# MKE15Z7 register map
Vendor: Freescale Semiconductor, Inc.; Series: Kinetis_E; File version: 1.6
CPU: CM0PLUS r0p0, little endian, no MPU, no FPU, VTOR, 2 interrupt priority bits
Registers are 32-bit, read-write, reset 0x0 unless marked. A register's access mark holds for its fields unless they carry their own. Offsets are from the block's base; [hi:lo] are bit positions; {n}, {i} and the like mark numbered series.

## SIM — System Integration Module
Base 0x40048000; register names take the prefix SIM_
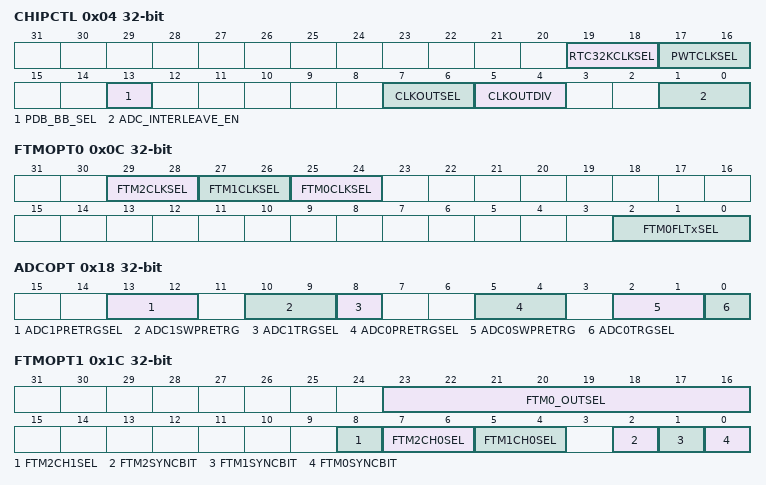
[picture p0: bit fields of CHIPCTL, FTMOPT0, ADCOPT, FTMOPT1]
0x04 CHIPCTL — Chip Control register
  [19:18] RTC32KCLKSEL — RTC 32K clock input select
    0=OSC32 clock output; 1=RTC_CLKIN
  [17:16] PWTCLKSEL — PWT clock source select
    0=PWT alternative clock is from the TCLK0 pin; 1=PWT alternative clock is from the TCLK1 pin; 2=PWT alternative clock is from the TCLK2 pin
  [13] PDB_BB_SEL — PDB back-to-back select
    0=PDB0 channel 0 back-to-back operation with ADC0 COCO[1:0] and PDB0 channel 1 back-to-back operation with ADC1 COCO[1:0]; 1=PDB0 Channel 0 back-to-back operation with COCO[0] of ADC0 and COCO[1] of ADC1 ; PDB0 Channel 1 back-to-back operation with COCO[0] of ADC1 and COCO[1] of ADC0
  [7:6] CLKOUTSEL — CLKOUT Select
    0=Reseved; 1=SCGCLKOUT(SIRC/FIRC/SOSC/LPFLL), see SCG_CLKOUTCNFG register; 2=RTC oscillator (OSC32) clock (32 kHz); 3=LPO clock (128 kHz)
  [5:4] CLKOUTDIV — CLKOUT divider ratio
    0=Divided by 1; 1=Divided by 2; 2=Divided by 4; 3=Divided by 8
  [1:0] ADC_INTERLEAVE_EN — ADC interleave channel enable
    0=No interleave channel
0x0C FTMOPT0 — FTM Option Register 0
  [29:28] FTM2CLKSEL — FTM2 External Clock Pin Select
    0=FTM2 external clock driven by TCLK0 pin; 1=FTM2 external clock driven by TCLK1 pin; 2=FTM2 external clock driven by TCLK2 pin; 3=No clock input
  [27:26] FTM1CLKSEL — FTM1 External Clock Pin Select
    0=FTM1 external clock driven by TCLK0 pin; 1=FTM1 external clock driven by TCLK1 pin; 2=FTM1 external clock driven by TCLK2 pin; 3=No clock input
  [25:24] FTM0CLKSEL — FTM0 External Clock Pin Select
    0=FTM0 external clock driven by TCLK0 pin; 1=FTM0 external clock driven by TCLK1 pin; 2=FTM0 external clock driven by TCLK2 pin; 3=No clock input
  [2:0] FTM0FLTxSEL — FTM0 Fault x Select
0x18 ADCOPT — ADC Options Register
  [13:12] ADC1PRETRGSEL — ADC1 pre-trigger source select
    0=PDB output; 1=TRGMUX output; 2=ADC1 software pre-trigger
  [10:9] ADC1SWPRETRG — ADC1 software pre-trigger sources
    {v}=software pre-trigger {v} (v=0..3)
  [8] ADC1TRGSEL — ADC1 trigger source select
    0=PDB output; 1=TRGMUX output
  [5:4] ADC0PRETRGSEL — ADC0 pre-trigger source select
    0=PDB output; 1=TRGMUX output; 2=ADC0 software pre-trigger
  [2:1] ADC0SWPRETRG — ADC0 software pre-trigger sources
    {v}=software pre-trigger {v} (v=0..3)
  [0] ADC0TRGSEL — ADC0 trigger source select
    0=PDB output; 1=TRGMUX output
0x1C FTMOPT1 — FTM Option Register 1
  [23:16] FTM0_OUTSEL — FTM0 channel modulation select with FTM1_CH1
    0=No modulation with FTM1_CH1; 1=Modulation with FTM1_CH1
  [8] FTM2CH1SEL — FTM2 CH1 Select
    0=FTM2_CH1 input; 1=exclusive OR of FTM2_CH0, FTM2_CH1, and FTM1_CH1
  [7:6] FTM2CH0SEL — FTM2 CH0 Select
    0=FTM2_CH0 input; 1=CMP0 output; 2=CMP1 output
  [5:4] FTM1CH0SEL — FTM1 CH0 Select
    0=FTM1_CH0 input; 1=CMP0 output; 2=CMP1 output
  [2] FTM2SYNCBIT
    0=No effect; 1=Write 1 to assert the TRIG1 input to FTM2. Software must clear this bit to allow other trigger sources to assert.
  [1] FTM1SYNCBIT
    0=No effect; 1=Write 1 to assert the TRIG1 input to FTM1. Software must clear this bit to allow other trigger sources to assert.
  [0] FTM0SYNCBIT
    0=No effect; 1=Write 1 to assert the TRIG1 input to FTM0. Software must clear this bit to allow other trigger sources to assert.
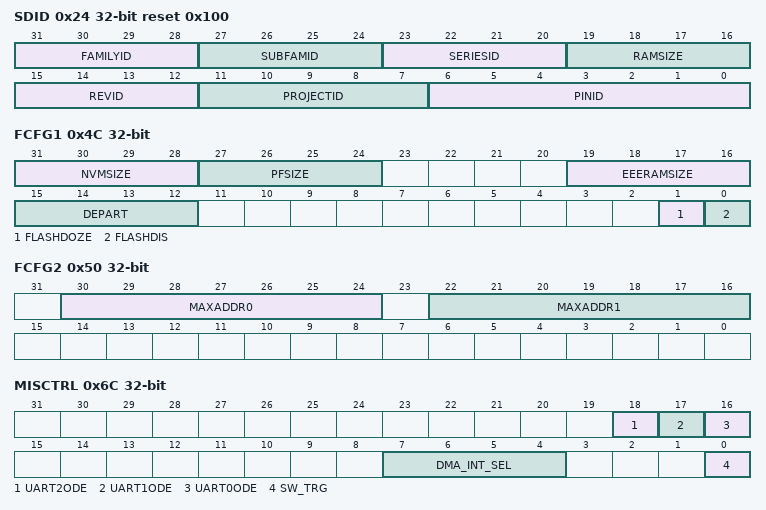
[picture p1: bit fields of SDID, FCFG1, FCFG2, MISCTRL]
0x24 SDID ro reset 0x100 (reset mask 0xF80) — System Device Identification Register
  [31:28] FAMILYID — Kinetis E-series Family ID
    0=KE0x Family (Entry level); 1=KE1x Family (Enhanced features); 3=KE3x Family (with SLCD)
  [27:24] SUBFAMID — Kinetis E-series Sub-Family ID
  [23:20] SERIESID — Kinetis Series ID
    2=Kinetis E+ series
  [19:16] RAMSIZE
    5=16 KB; 6=32 KB
  [15:12] REVID — Device revision number
  [11:7] PROJECTID
  [6:0] PINID — Pin identification
    7=64-pin; 8=80-pin; 10=100-pin
0x4C FCFG1 (reset mask 0xF00FFF) — Flash Configuration Register 1
  [31:28] NVMSIZE ro — FlexNVM size
    0=0 KB of FlexNVM; 3=32 KB of FlexNVM
  [27:24] PFSIZE ro — Program flash size
    7=128 KB of program flash memory, 4 KB protection region; 9=256 KB of program flash memory, 8 KB protection region
  [19:16] EEERAMSIZE ro — EEE SRAM SIZE
    3=2 KB; 4=1 KB; 5=512 Bytes; 6=256 Bytes; 7=128 Bytes; 8=64 Bytes; 9=32 Bytes
  [15:12] DEPART ro — FlexNVM partition
  [1] FLASHDOZE
    0=Flash remains enabled during Doze mode; 1=Flash is disabled for the duration of Doze mode
  [0] FLASHDIS — Flash Disable
    0=Flash is enabled; 1=Flash is disabled
0x50 FCFG2 ro reset not defined — Flash Configuration Register 2
  [30:24] MAXADDR0 — Max address block 0
  [22:16] MAXADDR1 — Max address block 1
0x54 UIDH ro — Unique Identification Register High
  [31:0] UID127_96 — Unique Identification
0x58 UIDMH ro — Unique Identification Register Mid-High
  [31:0] UID95_64 — Unique Identification
0x5C UIDML ro — Unique Identification Register Mid Low
  [31:0] UID63_32 — Unique Identification
0x60 UIDL ro — Unique Identification Register Low
  [31:0] UID31_0 — Unique Identification
0x6C MISCTRL — Miscellaneous Control register
  [18] UART2ODE — UART2 Open Drain Enable
    0=Open drain is disabled on UART2; 1=Open drain is enabled on UART2
  [17] UART1ODE — UART1 Open Drain Enable
    0=Open drain is disabled on UART1; 1=Open drain is enabled on UART1
  [16] UART0ODE — UART0 Open Drain Enable
    0=Open drain is disabled on UART0; 1=Open drain is enabled on UART0
  [7:4] DMA_INT_SEL — DMA channel interrupt OR select
  [0] SW_TRG — Software Trigger bit to TRGMUX
